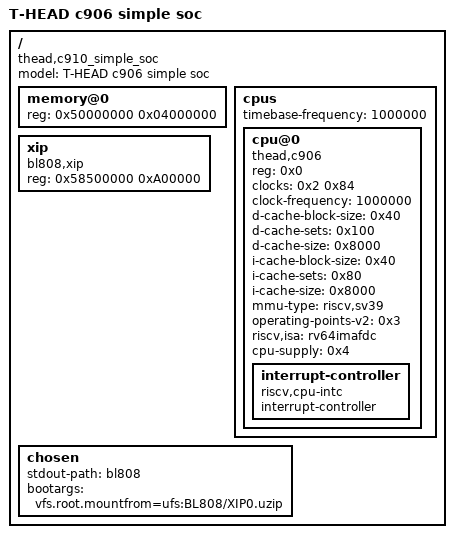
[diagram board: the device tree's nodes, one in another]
/dts-v1/;
/ {
  model = "T-HEAD c906 simple soc";
  compatible = "thead,c910_simple_soc";
  #address-cells = <1>;
  #size-cells = <1>;

  memory@0 {
    device_type = "memory";
    reg = <0x50000000 0x04000000>;
  };

  cpus {

    #address-cells = <0x1>;
    #size-cells = <0x0>;
    timebase-frequency = <1000000>;
    cpu@0 {
      compatible = "thead,c906", "riscv";
      device_type = "cpu";
      reg = <0x0>;
      clocks = <0x2 0x84>;
      clock-frequency = <1000000>;
      #cooling-cells = <0x2>;
      d-cache-block-size = <0x40>;
      d-cache-sets = <0x100>;
      d-cache-size = <0x8000>;
      i-cache-block-size = <0x40>;
      i-cache-sets = <0x80>;
      i-cache-size = <0x8000>;
      mmu-type = "riscv,sv39";
      operating-points-v2 = <0x3>;
      riscv,isa = "rv64imafdc";
      cpu-supply = <0x4>;
      phandle = <0xa>;
      interrupt-controller {

       compatible = "riscv,cpu-intc";
       #address-cells = <0x0>;
       interrupt-controller;
       #interrupt-cells = <0x1>;
       phandle = <0x35>;
      };
    };
  };

  xip {
      compatible = "bl808,xip";
      /* assigned-addresses = <0x58500000 0xA00000>; */
      reg = <0x58500000 0xA00000>;
  };

  chosen {
    stdout-path = "bl808";
    bootargs = "vfs.root.mountfrom=ufs:BL808/XIP0.uzip";
  };
};
